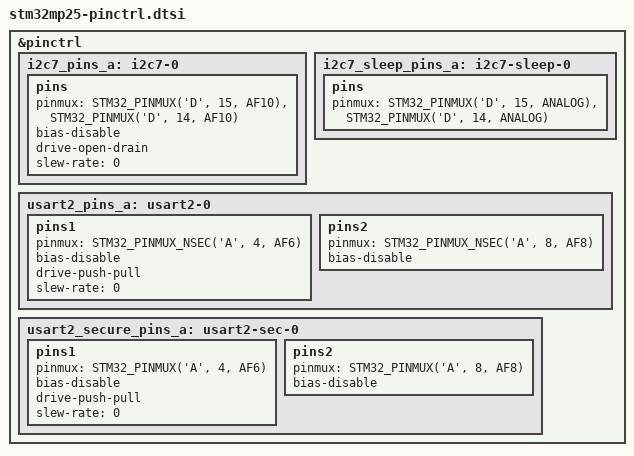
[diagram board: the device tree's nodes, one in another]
// SPDX-License-Identifier: (GPL-2.0-or-later OR BSD-3-Clause)
/*
 * Copyright (C) STMicroelectronics 2023 - All Rights Reserved
 * Author: Alexandre Torgue <alexandre.torgue@foss.st.com> for STMicroelectronics.
 */
#include <dt-bindings/pinctrl/stm32-pinfunc.h>

&pinctrl {
	i2c7_pins_a: i2c7-0 {
		pins {
			pinmux = <STM32_PINMUX('D', 15, AF10)>, /* I2C7_SCL */
				 <STM32_PINMUX('D', 14, AF10)>; /* I2C7_SDA */
			bias-disable;
			drive-open-drain;
			slew-rate = <0>;
		};
	};

	i2c7_sleep_pins_a: i2c7-sleep-0 {
		pins {
			pinmux = <STM32_PINMUX('D', 15, ANALOG)>, /* I2C7_SCL */
				 <STM32_PINMUX('D', 14, ANALOG)>; /* I2C7_SDA */
		};
	};

	usart2_pins_a: usart2-0 {
		pins1 {
			pinmux = <STM32_PINMUX_NSEC('A', 4, AF6)>; /* USART2_TX */
			bias-disable;
			drive-push-pull;
			slew-rate = <0>;
		};
		pins2 {
			pinmux = <STM32_PINMUX_NSEC('A', 8, AF8)>; /* USART2_RX */
			bias-disable;
		};
	};

	usart2_secure_pins_a: usart2-sec-0 {
		pins1 {
			pinmux = <STM32_PINMUX('A', 4, AF6)>; /* USART2_TX */
			bias-disable;
			drive-push-pull;
			slew-rate = <0>;
		};
		pins2 {
			pinmux = <STM32_PINMUX('A', 8, AF8)>; /* USART2_RX */
			bias-disable;
		};
	};
};
